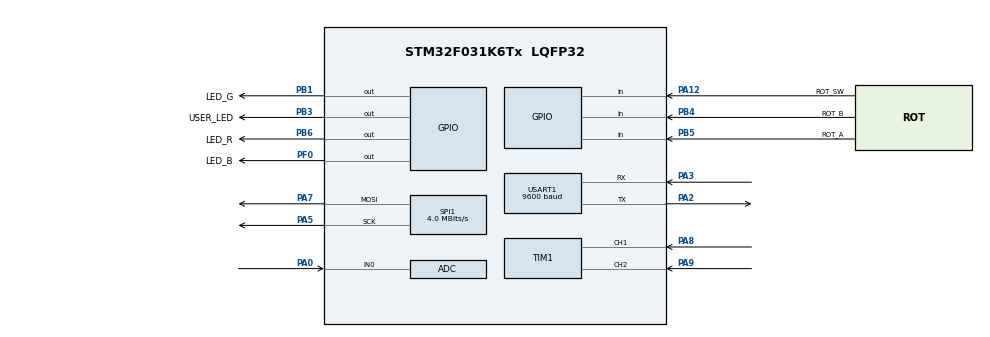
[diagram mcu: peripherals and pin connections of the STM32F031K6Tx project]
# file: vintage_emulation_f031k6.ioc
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ADC.ClockPrescaler=ADC_CLOCK_ASYNC_DIV1
ADC.ContinuousConvMode=DISABLE
ADC.SamplingTime=ADC_SAMPLETIME_239CYCLES_5
Mcu.Family=STM32F0
Mcu.Name=STM32F031K6Tx
Mcu.Package=LQFP32
NVIC.ADC1_IRQn=true\:0\:0\:false\:false\:true\:true\:true\:true
NVIC.USART1_IRQn=true\:0\:0\:false\:false\:true\:true\:true\:true
PA0.Mode=IN0
PA0.Signal=ADC_IN0
PA12.GPIO_Label=ROT_SW
PA12.Signal=GPIO_Input
PA13.GPIO_Label=SWDIO
PA13.Mode=Serial_Wire
PA13.Signal=SYS_SWDIO
PA14.GPIO_Label=SWCLK
PA14.Mode=Serial_Wire
PA14.Signal=SYS_SWCLK
PA2.Mode=Asynchronous
PA2.Signal=USART1_TX
PA3.Mode=Asynchronous
PA3.Signal=USART1_RX
PA5.Mode=TX_Only_Simplex_Unidirect_Master
PA5.Signal=SPI1_SCK
PA7.Mode=TX_Only_Simplex_Unidirect_Master
PA7.Signal=SPI1_MOSI
PA8.Signal=S_TIM1_CH1
PA9.Signal=S_TIM1_CH2
PB1.GPIO_Label=LED_G
PB1.Signal=GPIO_Output
PB3.GPIO_Label=USER_LED
PB3.Signal=GPIO_Output
PB4.GPIO_Label=ROT_B
PB4.GPIO_PuPd=GPIO_PULLUP
PB4.Signal=GPIO_Input
PB5.GPIO_Label=ROT_A
PB5.GPIO_PuPd=GPIO_PULLUP
PB5.Signal=GPIO_Input
PB6.GPIO_Label=LED_R
PB6.Signal=GPIO_Output
PF0-OSC_IN.GPIO_Label=LED_B
PF0-OSC_IN.Signal=GPIO_Output
ProjectManager.HeapSize=0x200
ProjectManager.StackSize=0x400
ProjectManager.TargetToolchain=STM32CubeIDE
SH.S_TIM1_CH1.0=TIM1_CH1,Encoder_Interface
SH.S_TIM1_CH2.0=TIM1_CH2,Encoder_Interface
SPI1.CalculateBaudRate=4.0 MBits/s
SPI1.Direction=SPI_DIRECTION_2LINES
SPI1.Mode=SPI_MODE_MASTER
SPI1.VirtualType=VM_MASTER
TIM1.AutoReloadPreload=TIM_AUTORELOAD_PRELOAD_ENABLE
TIM1.EncoderMode=TIM_ENCODERMODE_TI12
TIM1.IC1Filter=15
TIM1.IC2Filter=15
USART1.BaudRate=9600
USART1.VirtualMode-Asynchronous=VM_ASYNC
VP_TIM3_VS_ClockSourceINT.Mode=Internal
board=NUCLEO-F031K6

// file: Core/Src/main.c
/* USER CODE BEGIN Header */
/**
  ******************************************************************************
  * @file           : main.c
  * @brief          : Main program body
  ******************************************************************************
  * @attention
  *
  * Copyright (c) 2024 STMicroelectronics.
  * All rights reserved.
  *
  * This software is licensed under terms that can be found in the LICENSE file
  * in the root directory of this software component.
  * If no LICENSE file comes with this software, it is provided AS-IS.
  *
  ******************************************************************************
  */
/* USER CODE END Header */
#include "main.h"

/* USER CODE BEGIN Includes */
#include "main_task.h"
/* USER CODE END Includes */

ADC_HandleTypeDef hadc;

SPI_HandleTypeDef hspi1;

TIM_HandleTypeDef htim1;
TIM_HandleTypeDef htim3;

void SystemClock_Config(void);
static void MX_GPIO_Init(void);
static void MX_USART1_UART_Init(void);
static void MX_SPI1_Init(void);
static void MX_TIM3_Init(void);
static void MX_ADC_Init(void);
static void MX_TIM1_Init(void);

int main(void)
{

  /* MCU Configuration--------------------------------------------------------*/

  /* Reset of all peripherals, Initializes the Flash interface and the Systick. */
  HAL_Init();

  /* Configure the system clock */
  SystemClock_Config();

  /* Initialize all configured peripherals */
  MX_GPIO_Init();
  MX_USART1_UART_Init();
  MX_SPI1_Init();
  MX_TIM3_Init();
  MX_ADC_Init();
  MX_TIM1_Init();
  /* USER CODE BEGIN 2 */

  main_task_init();
  /* USER CODE END 2 */

  /* Infinite loop */
  while (1)
  {

    /* USER CODE BEGIN 3 */
	  main_task_run(NULL);
  }
  /* USER CODE END 3 */
}

void SystemClock_Config(void)
{
  RCC_OscInitTypeDef RCC_OscInitStruct = {0};
  RCC_ClkInitTypeDef RCC_ClkInitStruct = {0};
  RCC_PeriphCLKInitTypeDef PeriphClkInit = {0};

  /** Initializes the RCC Oscillators according to the specified parameters
  * in the RCC_OscInitTypeDef structure.
  */
  RCC_OscInitStruct.OscillatorType = RCC_OSCILLATORTYPE_HSI|RCC_OSCILLATORTYPE_HSI14;
  RCC_OscInitStruct.HSIState = RCC_HSI_ON;
  RCC_OscInitStruct.HSI14State = RCC_HSI14_ON;
  RCC_OscInitStruct.HSICalibrationValue = RCC_HSICALIBRATION_DEFAULT;
  RCC_OscInitStruct.HSI14CalibrationValue = 16;
  RCC_OscInitStruct.PLL.PLLState = RCC_PLL_NONE;
  if (HAL_RCC_OscConfig(&RCC_OscInitStruct) != HAL_OK)
  {
    Error_Handler();
  }

  /** Initializes the CPU, AHB and APB buses clocks
  */
  RCC_ClkInitStruct.ClockType = RCC_CLOCKTYPE_HCLK|RCC_CLOCKTYPE_SYSCLK
                              |RCC_CLOCKTYPE_PCLK1;
  RCC_ClkInitStruct.SYSCLKSource = RCC_SYSCLKSOURCE_HSI;
  RCC_ClkInitStruct.AHBCLKDivider = RCC_SYSCLK_DIV1;
  RCC_ClkInitStruct.APB1CLKDivider = RCC_HCLK_DIV1;

  if (HAL_RCC_ClockConfig(&RCC_ClkInitStruct, FLASH_LATENCY_0) != HAL_OK)
  {
    Error_Handler();
  }
  PeriphClkInit.PeriphClockSelection = RCC_PERIPHCLK_USART1;
  PeriphClkInit.Usart1ClockSelection = RCC_USART1CLKSOURCE_PCLK1;
  if (HAL_RCCEx_PeriphCLKConfig(&PeriphClkInit) != HAL_OK)
  {
    Error_Handler();
  }
}

static void MX_ADC_Init(void)
{

  ADC_ChannelConfTypeDef sConfig = {0};

  /** Configure the global features of the ADC (Clock, Resolution, Data Alignment and number of conversion)
  */
  hadc.Instance = ADC1;
  hadc.Init.ClockPrescaler = ADC_CLOCK_ASYNC_DIV1;
  hadc.Init.Resolution = ADC_RESOLUTION_12B;
  hadc.Init.DataAlign = ADC_DATAALIGN_RIGHT;
  hadc.Init.ScanConvMode = ADC_SCAN_DIRECTION_FORWARD;
  hadc.Init.EOCSelection = ADC_EOC_SINGLE_CONV;
  hadc.Init.LowPowerAutoWait = DISABLE;
  hadc.Init.LowPowerAutoPowerOff = DISABLE;
  hadc.Init.ContinuousConvMode = DISABLE;
  hadc.Init.DiscontinuousConvMode = DISABLE;
  hadc.Init.ExternalTrigConv = ADC_SOFTWARE_START;
  hadc.Init.ExternalTrigConvEdge = ADC_EXTERNALTRIGCONVEDGE_NONE;
  hadc.Init.DMAContinuousRequests = DISABLE;
  hadc.Init.Overrun = ADC_OVR_DATA_PRESERVED;
  if (HAL_ADC_Init(&hadc) != HAL_OK)
  {
    Error_Handler();
  }

  /** Configure for the selected ADC regular channel to be converted.
  */
  sConfig.Channel = ADC_CHANNEL_0;
  sConfig.Rank = ADC_RANK_CHANNEL_NUMBER;
  sConfig.SamplingTime = ADC_SAMPLETIME_239CYCLES_5;
  if (HAL_ADC_ConfigChannel(&hadc, &sConfig) != HAL_OK)
  {
    Error_Handler();
  }
  /* USER CODE BEGIN ADC_Init 2 */
  HAL_ADC_Start_IT(&hadc);
  /* USER CODE END ADC_Init 2 */

}

static void MX_SPI1_Init(void)
{

  /* SPI1 parameter configuration*/
  hspi1.Instance = SPI1;
  hspi1.Init.Mode = SPI_MODE_MASTER;
  hspi1.Init.Direction = SPI_DIRECTION_2LINES;
  hspi1.Init.DataSize = SPI_DATASIZE_4BIT;
  hspi1.Init.CLKPolarity = SPI_POLARITY_LOW;
  hspi1.Init.CLKPhase = SPI_PHASE_1EDGE;
  hspi1.Init.NSS = SPI_NSS_SOFT;
  hspi1.Init.BaudRatePrescaler = SPI_BAUDRATEPRESCALER_2;
  hspi1.Init.FirstBit = SPI_FIRSTBIT_MSB;
  hspi1.Init.TIMode = SPI_TIMODE_DISABLE;
  hspi1.Init.CRCCalculation = SPI_CRCCALCULATION_DISABLE;
  hspi1.Init.CRCPolynomial = 7;
  hspi1.Init.CRCLength = SPI_CRC_LENGTH_DATASIZE;
  hspi1.Init.NSSPMode = SPI_NSS_PULSE_ENABLE;
  if (HAL_SPI_Init(&hspi1) != HAL_OK)
  {
    Error_Handler();
  }

}

static void MX_TIM1_Init(void)
{

  TIM_Encoder_InitTypeDef sConfig = {0};
  TIM_MasterConfigTypeDef sMasterConfig = {0};

  htim1.Instance = TIM1;
  htim1.Init.Prescaler = 0;
  htim1.Init.CounterMode = TIM_COUNTERMODE_UP;
  htim1.Init.Period = 65535;
  htim1.Init.ClockDivision = TIM_CLOCKDIVISION_DIV1;
  htim1.Init.RepetitionCounter = 0;
  htim1.Init.AutoReloadPreload = TIM_AUTORELOAD_PRELOAD_ENABLE;
  sConfig.EncoderMode = TIM_ENCODERMODE_TI12;
  sConfig.IC1Polarity = TIM_ICPOLARITY_RISING;
  sConfig.IC1Selection = TIM_ICSELECTION_DIRECTTI;
  sConfig.IC1Prescaler = TIM_ICPSC_DIV1;
  sConfig.IC1Filter = 15;
  sConfig.IC2Polarity = TIM_ICPOLARITY_RISING;
  sConfig.IC2Selection = TIM_ICSELECTION_DIRECTTI;
  sConfig.IC2Prescaler = TIM_ICPSC_DIV1;
  sConfig.IC2Filter = 15;
  if (HAL_TIM_Encoder_Init(&htim1, &sConfig) != HAL_OK)
  {
    Error_Handler();
  }
  sMasterConfig.MasterOutputTrigger = TIM_TRGO_RESET;
  sMasterConfig.MasterSlaveMode = TIM_MASTERSLAVEMODE_DISABLE;
  if (HAL_TIMEx_MasterConfigSynchronization(&htim1, &sMasterConfig) != HAL_OK)
  {
    Error_Handler();
  }

}

static void MX_TIM3_Init(void)
{

  TIM_ClockConfigTypeDef sClockSourceConfig = {0};
  TIM_MasterConfigTypeDef sMasterConfig = {0};

  htim3.Instance = TIM3;
  htim3.Init.Prescaler = 0;
  htim3.Init.CounterMode = TIM_COUNTERMODE_UP;
  htim3.Init.Period = 65535;
  htim3.Init.ClockDivision = TIM_CLOCKDIVISION_DIV1;
  htim3.Init.AutoReloadPreload = TIM_AUTORELOAD_PRELOAD_DISABLE;
  if (HAL_TIM_Base_Init(&htim3) != HAL_OK)
  {
    Error_Handler();
  }
  sClockSourceConfig.ClockSource = TIM_CLOCKSOURCE_INTERNAL;
  if (HAL_TIM_ConfigClockSource(&htim3, &sClockSourceConfig) != HAL_OK)
  {
    Error_Handler();
  }
  sMasterConfig.MasterOutputTrigger = TIM_TRGO_RESET;
  sMasterConfig.MasterSlaveMode = TIM_MASTERSLAVEMODE_DISABLE;
  if (HAL_TIMEx_MasterConfigSynchronization(&htim3, &sMasterConfig) != HAL_OK)
  {
    Error_Handler();
  }

}

static void MX_USART1_UART_Init(void)
{

  LL_USART_InitTypeDef USART_InitStruct = {0};

  LL_GPIO_InitTypeDef GPIO_InitStruct = {0};

  /* Peripheral clock enable */
  LL_APB1_GRP2_EnableClock(LL_APB1_GRP2_PERIPH_USART1);

  LL_AHB1_GRP1_EnableClock(LL_AHB1_GRP1_PERIPH_GPIOA);
  /**USART1 GPIO Configuration
  PA2   ------> USART1_TX
  PA3   ------> USART1_RX
  */
  GPIO_InitStruct.Pin = LL_GPIO_PIN_2;
  GPIO_InitStruct.Mode = LL_GPIO_MODE_ALTERNATE;
  GPIO_InitStruct.Speed = LL_GPIO_SPEED_FREQ_HIGH;
  GPIO_InitStruct.OutputType = LL_GPIO_OUTPUT_PUSHPULL;
  GPIO_InitStruct.Pull = LL_GPIO_PULL_NO;
  GPIO_InitStruct.Alternate = LL_GPIO_AF_1;
  LL_GPIO_Init(GPIOA, &GPIO_InitStruct);

  GPIO_InitStruct.Pin = LL_GPIO_PIN_3;
  GPIO_InitStruct.Mode = LL_GPIO_MODE_ALTERNATE;
  GPIO_InitStruct.Speed = LL_GPIO_SPEED_FREQ_HIGH;
  GPIO_InitStruct.OutputType = LL_GPIO_OUTPUT_PUSHPULL;
  GPIO_InitStruct.Pull = LL_GPIO_PULL_NO;
  GPIO_InitStruct.Alternate = LL_GPIO_AF_1;
  LL_GPIO_Init(GPIOA, &GPIO_InitStruct);

  /* USART1 interrupt Init */
  NVIC_SetPriority(USART1_IRQn, 0);
  NVIC_EnableIRQ(USART1_IRQn);

  USART_InitStruct.BaudRate = 9600;
  USART_InitStruct.DataWidth = LL_USART_DATAWIDTH_8B;
  USART_InitStruct.StopBits = LL_USART_STOPBITS_1;
  USART_InitStruct.Parity = LL_USART_PARITY_NONE;
  USART_InitStruct.TransferDirection = LL_USART_DIRECTION_TX_RX;
  USART_InitStruct.HardwareFlowControl = LL_USART_HWCONTROL_NONE;
  USART_InitStruct.OverSampling = LL_USART_OVERSAMPLING_16;
  LL_USART_Init(USART1, &USART_InitStruct);
  LL_USART_DisableIT_CTS(USART1);
  LL_USART_ConfigAsyncMode(USART1);
  LL_USART_Enable(USART1);

}

static void MX_GPIO_Init(void)
{
  GPIO_InitTypeDef GPIO_InitStruct = {0};

  /* GPIO Ports Clock Enable */
  __HAL_RCC_GPIOF_CLK_ENABLE();
  __HAL_RCC_GPIOA_CLK_ENABLE();
  __HAL_RCC_GPIOB_CLK_ENABLE();

  /*Configure GPIO pin Output Level */
  HAL_GPIO_WritePin(LED_B_GPIO_Port, LED_B_Pin, GPIO_PIN_RESET);

  /*Configure GPIO pin Output Level */
  HAL_GPIO_WritePin(GPIOB, LED_G_Pin|USER_LED_Pin|LED_R_Pin, GPIO_PIN_RESET);

  /*Configure GPIO pin : LED_B_Pin */
  GPIO_InitStruct.Pin = LED_B_Pin;
  GPIO_InitStruct.Mode = GPIO_MODE_OUTPUT_PP;
  GPIO_InitStruct.Pull = GPIO_NOPULL;
  GPIO_InitStruct.Speed = GPIO_SPEED_FREQ_LOW;
  HAL_GPIO_Init(LED_B_GPIO_Port, &GPIO_InitStruct);

  /*Configure GPIO pins : LED_G_Pin USER_LED_Pin LED_R_Pin */
  GPIO_InitStruct.Pin = LED_G_Pin|USER_LED_Pin|LED_R_Pin;
  GPIO_InitStruct.Mode = GPIO_MODE_OUTPUT_PP;
  GPIO_InitStruct.Pull = GPIO_NOPULL;
  GPIO_InitStruct.Speed = GPIO_SPEED_FREQ_LOW;
  HAL_GPIO_Init(GPIOB, &GPIO_InitStruct);

  /*Configure GPIO pin : ROT_SW_Pin */
  GPIO_InitStruct.Pin = ROT_SW_Pin;
  GPIO_InitStruct.Mode = GPIO_MODE_INPUT;
  GPIO_InitStruct.Pull = GPIO_NOPULL;
  HAL_GPIO_Init(ROT_SW_GPIO_Port, &GPIO_InitStruct);

  /*Configure GPIO pins : ROT_B_Pin ROT_A_Pin */
  GPIO_InitStruct.Pin = ROT_B_Pin|ROT_A_Pin;
  GPIO_InitStruct.Mode = GPIO_MODE_INPUT;
  GPIO_InitStruct.Pull = GPIO_PULLUP;
  HAL_GPIO_Init(GPIOB, &GPIO_InitStruct);

}

void Error_Handler(void)
{
  __disable_irq();
  while (1)
  {
  }
}
